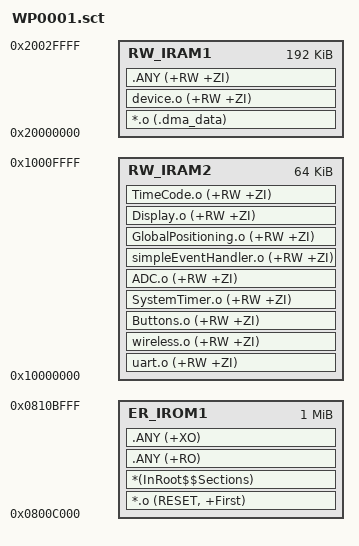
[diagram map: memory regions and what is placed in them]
; *************************************************************
; *** Scatter-Loading Description File generated by uVision ***
; *************************************************************

LR_IROM1 0x0800C000 0x00100000  {    ; load region size_region
  ER_IROM1 0x0800C000 0x00100000  {  ; load address = execution address
   *.o (RESET, +First)
   *(InRoot$$Sections)
   .ANY (+RO)
   .ANY (+XO)
  }
  RW_IRAM1 0x20000000 0x00030000  {  ; RW data (Main SRAM - DMA accessible)
   *.o (.dma_data)                    ; DMA buffers forced here via __attribute__((section(".dma_data")))
   device.o (+RW +ZI)
   .ANY (+RW +ZI)
  }
  RW_IRAM2 0x10000000 0x00010000  { ; CCM RAM - NO DMA access possible
   ; uart.o and wireless.o are placed in CCM because their ring buffers are
   ; interrupt-driven (not DMA). Only hdma_uart8_tx uses DMA and is forced
   ; to Main SRAM via __attribute__((section(".dma_data"))).
   ; buf_DMX_DMA is in device.o which is already in Main SRAM.
   uart.o (+RW +ZI)
   wireless.o (+RW +ZI)
   Buttons.o (+RW +ZI)
   SystemTimer.o (+RW +ZI)
   ADC.o (+RW +ZI)
   simpleEventHandler.o (+RW +ZI)
   GlobalPositioning.o (+RW +ZI)
   Display.o (+RW +ZI)
   TimeCode.o (+RW +ZI)
  }
}

